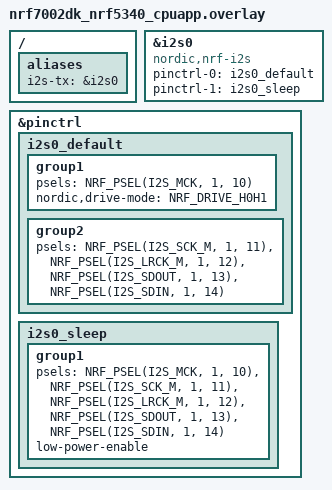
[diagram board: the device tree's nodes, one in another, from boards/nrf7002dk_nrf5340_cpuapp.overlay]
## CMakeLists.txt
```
#
# Copyright (c) 2022 Nordic Semiconductor ASA
#
# SPDX-License-Identifier: LicenseRef-Nordic-5-Clause
#

cmake_minimum_required(VERSION 3.20.0)

find_package(Zephyr REQUIRED HINTS $ENV{ZEPHYR_BASE})
project(nrf_wifi_audio_player)

FILE(GLOB app_sources src/*.c)


message("show app_sources::")
message("${app_sources}")

if (CONFIG_NRF700X_AP_MODE)
        list(FILTER app_sources EXCLUDE REGEX ".*wifi_station_mode\\.c$")
else()
        list(FILTER app_sources EXCLUDE REGEX ".*wifi_softap_mode\\.c$")
endif()

target_sources(app PRIVATE ${app_sources})
target_include_directories(app PRIVATE src)
target_include_directories(app PUBLIC ${ZEPHYR_BASE}/subsys/net/ip)
```

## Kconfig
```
#
# Copyright (c) 2022 Nordic Semiconductor
#
# SPDX-License-Identifier: LicenseRef-Nordic-5-Clause
#

source "Kconfig.zephyr"

menu "Nordic WiFi Auido Player"

if NRF700X_AP_MODE

config SAMPLE_SOCKET_TCP
	bool "Use TCP sockets"
	default n
	help
	  Enable this to use TCP instead of UDP for sockets.

config SOFTAP_DHCPV4_SERVER
	bool "DHCPv4 server"
	select NET_DHCPV4_SERVER
	default y
	help
	  Enable this to configure DHCPV4 server settings.

config SOFTAP_DHCPV4_POOL_START
	string "Start address of DHCPv4 pool"
	default "192.168.1.2"
	help
	  Set the start IP address of DHCPv4 pool.

config SOFTAP_REG_DOMAIN
	string "The ISO/IEC alpha2 country code"
	default "00"
	help
	  Set the ISO/IEC alpha2 country code for the country in
	  which the device is currently operating.
	  For world regulatory, use "00".

choice SOFTAP_FREQUENCY_BAND
	prompt "Wi-Fi frequency band for SoftAp"
	default SOFTAP_2_4GHz

config SOFTAP_2_4GHz
	bool "2.4 GHz band"
	help
	  Enable this option if the SoftAP should operate in the 2.4 GHz band.

config SOFTAP_5GHz
	bool "5 GHz band"
	help
	  Enable this option if the SoftAP should operate in the 5 GHz band.
	  Ensure that you have the appropriate regulatory settings configured.
endchoice

config SOFTAP_CHANNEL
	int "SoftAP channel"
	range 1 255
	default 1 if SOFTAP_2_4GHz
	default 36 if SOFTAP_5GHz
	help
	  Set the Wi-Fi channel on which the SoftAP will operate.

config SOFTAP_SSID
	string "SoftAP SSID"
	default "Myssid"
	help
	  Set the SSID (Service Set Identifier) for the SoftAP.
	  This is the name that will be broadcasted for client(s) to connect.

choice  SOFTAP_KEY_MGMT_SELECT
	prompt "Security option for SoftAP"
	default SOFTAP_KEY_MGMT_WPA2

config SOFTAP_KEY_MGMT_NONE
	bool "Open security"
	help
	  Enable for open security

config SOFTAP_KEY_MGMT_WPA2
	bool "WPA2 security"
	help
	  Enable for WPA2 security

config SOFTAP_KEY_MGMT_WPA2_256
	bool "WPA2 SHA 256 security"
	help
	  Enable for WPA2-PSK-256 security.

config SOFTAP_KEY_MGMT_WPA3
	bool "WPA3 security"
	help
	  Enable for WPA3 security.
endchoice

config SOFTAP_PASSWORD
	string "Passphrase (WPA2) or password (WPA3)"
	default "Mypassword"
	help
	  Set the password for SoftAP.

config SOFTAP_MAX_STATIONS
	int "Maximum number of stations"
	# Experimental support for one, but in future support for up to 8 (nRF70 limitation)
	range 1 1
	default 1
	help
	  Set the maximum number of stations allowed to connect to the SoftAP.

config SOFTAP_START_WIFI_THREAD_STACK_SIZE
	int "Stack size for Wi-Fi start thread"
	default 4096
	help
	  Set the stack size for the Wi-Fi start thread.   

endif #if NRF700X_AP_MODE

endmenu
```

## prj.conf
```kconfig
#
# Copyright (c) 2022 Nordic Semiconductor ASA
#
# SPDX-License-Identifier: LicenseRef-Nordic-5-Clause
#

# Wi-Fi
CONFIG_WIFI=y
CONFIG_WIFI_NRF700X=y

# WPA supplicant
CONFIG_WPA_SUPP=y

# Station Mode
# Configure the Wi-Fi credentials
CONFIG_WIFI_CREDENTIALS=y
CONFIG_WIFI_CREDENTIALS_STATIC=n
CONFIG_WIFI_CREDENTIALS_BACKEND_SETTINGS=y
CONFIG_FLASH=y
CONFIG_FLASH_PAGE_LAYOUT=y
CONFIG_FLASH_MAP=y
CONFIG_NVS=y
CONFIG_SETTINGS=y
CONFIG_SETTINGS_NVS=y
# Enable support for shell commands
CONFIG_SHELL=y
CONFIG_SHELL_STACK_SIZE=8192
CONFIG_WIFI_CREDENTIALS_SHELL=y

# Networking Management API
# Enable the Network Management relevant configurations
CONFIG_NET_MGMT=y
CONFIG_NET_MGMT_EVENT=y
CONFIG_NET_MGMT_EVENT_INFO=y
CONFIG_NET_MGMT_EVENT_STACK_SIZE=4096
CONFIG_NET_CONNECTION_MANAGER=y
#CONFIG_L2_WIFI_CONNECTIVITY=y

# Logging
CONFIG_LOG=y
CONFIG_LOG_DEFAULT_LEVEL=3

# DK library
CONFIG_DK_LIBRARY=y

# Networking
CONFIG_NETWORKING=y
CONFIG_NET_NATIVE=y
CONFIG_NET_SOCKETS=y
CONFIG_NET_LOG=y
CONFIG_NET_IPV4=y
CONFIG_NET_TCP=y
CONFIG_NET_UDP=y
CONFIG_NET_DHCPV4=y

CONFIG_NET_PKT_RX_COUNT=8
CONFIG_NET_PKT_TX_COUNT=8

# Below section is the primary contributor to SRAM and is currently
# tuned for performance, but this will be revisited in the future.
CONFIG_NET_BUF_RX_COUNT=16
CONFIG_NET_BUF_TX_COUNT=16
CONFIG_NET_BUF_DATA_SIZE=1500
CONFIG_HEAP_MEM_POOL_SIZE=153600
CONFIG_NET_TC_TX_COUNT=1

CONFIG_NET_IF_UNICAST_IPV4_ADDR_COUNT=1
CONFIG_NET_MAX_CONTEXTS=5
CONFIG_NET_CONTEXT_SYNC_RECV=y

CONFIG_INIT_STACKS=y

CONFIG_NET_L2_ETHERNET=y

CONFIG_NET_CONFIG_SETTINGS=y
CONFIG_NET_CONFIG_INIT_TIMEOUT=0

CONFIG_NET_SOCKETS_POLL_MAX=10

CONFIG_NET_CONFIG_MY_IPV4_ADDR="192.168.1.1"
CONFIG_NET_CONFIG_MY_IPV4_NETMASK="255.255.255.0"
CONFIG_NET_CONFIG_MY_IPV4_GW="192.168.1.1"

# printing of scan results puts pressure on queues in new locking
# design in net_mgmt. So, use a higher timeout for a crowded
# environment.
CONFIG_NET_MGMT_EVENT_QUEUE_TIMEOUT=5000

# Memories
CONFIG_MAIN_STACK_SIZE=8192
CONFIG_SYSTEM_WORKQUEUE_STACK_SIZE=4096
CONFIG_NET_TX_STACK_SIZE=8192
CONFIG_NET_RX_STACK_SIZE=8192

# Kernel options
CONFIG_ENTROPY_GENERATOR=y

CONFIG_DEBUG=y

# Enable I2S
CONFIG_I2S=y
CONFIG_I2S_LOG_LEVEL_ERR=y
```

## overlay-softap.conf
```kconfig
# Disable WiFi Station Mode first



# Enable Soft AP Mode
CONFIG_NRF700X_AP_MODE=y
CONFIG_WPA_SUPP_AP=y
CONFIG_WPA_SUPP_LOG_LEVEL_INF=y
CONFIG_WIFI_READY_LIB=y

CONFIG_SOFTAP_SAMPLE_5GHz=y
CONFIG_SOFTAP_SAMPLE_CHANNEL=36
CONFIG_SOFTAP_SAMPLE_REG_DOMAIN="NO"
CONFIG_SOFTAP_SAMPLE_SSID="WiFi_Audio_AP"
CONFIG_SOFTAP_SAMPLE_PASSWORD="Auido@WiFi"
CONFIG_FILE_SYSTEM=y
```

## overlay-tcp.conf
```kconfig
CONFIG_SAMPLE_SOCKET_TCP=y
```

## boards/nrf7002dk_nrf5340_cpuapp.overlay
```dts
/*
 * Copyright 2023 NXP
 *
 * SPDX-License-Identifier: Apache-2.0
 */

&i2s0 {
	compatible = "nordic,nrf-i2s";
	status = "okay";
	pinctrl-0 = <&i2s0_default>;
	pinctrl-1 = <&i2s0_sleep>;
	pinctrl-names = "default", "sleep";
};

&pinctrl {
	i2s0_default: i2s0_default {
		group1 {
			psels = <NRF_PSEL(I2S_MCK, 1, 10)>;
			nordic,drive-mode = <NRF_DRIVE_H0H1>;
		};
		group2 {
			psels = <NRF_PSEL(I2S_SCK_M, 1, 11)>,
				<NRF_PSEL(I2S_LRCK_M, 1, 12)>,
				<NRF_PSEL(I2S_SDOUT, 1, 13)>,
				<NRF_PSEL(I2S_SDIN, 1, 14)>;
		};
	};

	i2s0_sleep: i2s0_sleep {
		group1 {
			psels = <NRF_PSEL(I2S_MCK, 1, 10)>,
				<NRF_PSEL(I2S_SCK_M, 1, 11)>,
				<NRF_PSEL(I2S_LRCK_M, 1, 12)>,
				<NRF_PSEL(I2S_SDOUT, 1, 13)>,
				<NRF_PSEL(I2S_SDIN, 1, 14)>;
			low-power-enable;
		};
	};
};

/ {
	aliases {
		i2s-tx = &i2s0;
	};
};
```

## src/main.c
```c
/*
 * Copyright (c) 2022 Nordic Semiconductor ASA
 *
 * SPDX-License-Identifier: LicenseRef-Nordic-5-Clause
 */

/** @file
 * @brief WiFi station sample
 */

#include <zephyr/logging/log.h>
LOG_MODULE_REGISTER(wifi_to_i2s, CONFIG_LOG_DEFAULT_LEVEL);

#include <stdio.h>
#include <zephyr/kernel.h>
#include <zephyr/drivers/i2s.h>
#include <zephyr/sys/iterable_sections.h>
#include "socket_util.h"

const struct device *dev_i2s = DEVICE_DT_GET(DT_ALIAS(i2s_tx));

#define NUM_BLOCKS 10
#define BLOCK_SIZE BUFFER_MAX_SIZE

#define I2S_TIMEOUT_MS 100

#define I2S_THREAD_STACKSIZE 8192
#define I2S_THREAD_PRIORITY 8

#ifdef CONFIG_NOCACHE_MEMORY
	#define MEM_SLAB_CACHE_ATTR __nocache
#else
	#define MEM_SLAB_CACHE_ATTR
#endif /* CONFIG_NOCACHE_MEMORY */

static char MEM_SLAB_CACHE_ATTR __aligned(WB_UP(32))
	_k_mem_slab_buf_tx_0_mem_slab[(NUM_BLOCKS) * WB_UP(BLOCK_SIZE)];

static STRUCT_SECTION_ITERABLE(k_mem_slab, tx_0_mem_slab) =
	Z_MEM_SLAB_INITIALIZER(tx_0_mem_slab, _k_mem_slab_buf_tx_0_mem_slab,
				WB_UP(BLOCK_SIZE), NUM_BLOCKS);

static uint32_t i2s_running = false;

int i2s_recover(void)
{
    LOG_INF("I2S driver is likely in error state, trying to recover");
    int ret = i2s_trigger(dev_i2s, I2S_DIR_TX, I2S_TRIGGER_PREPARE);
    if (ret < 0) {
        LOG_ERR("Failed to recover I2S. Please reset board");
    }
    return ret;
}


int i2s_drain_tx(void)
{
    /* Drain TX queue */
	LOG_INF("Triggered DRAIN");
    int ret = i2s_trigger(dev_i2s, I2S_DIR_TX, I2S_TRIGGER_DRAIN);
    i2s_running = false;
	if (ret < 0) {
		LOG_ERR("I2S DRAIN not triggered correctly: %d", ret);
        //Try to fix by reconfiguring driver
        ret = i2s_recover();
        if(ret <0)
        {
            LOG_ERR("Could not recover I2S, please reset board");
            return ret;
        }
        LOG_INF("Recover successful!");
		return ret;
	}
    
}

int i2s_send_data(uint8_t *data, uint16_t len)
{
    int ret;
    int curr_block_idx = 0;
    void *tx_block[NUM_BLOCKS];

    if(!i2s_running)
    {
        ret = k_mem_slab_alloc(&tx_0_mem_slab, &tx_block[curr_block_idx], K_FOREVER);
        if(ret < 0)
        {
            LOG_ERR("Could not allocate memory slab: %d", ret);
            return ret;
        }
        memset(tx_block[curr_block_idx],0x00, BLOCK_SIZE);
        memcpy(tx_block[curr_block_idx], data, MIN(len, BLOCK_SIZE));
        /* Send first block */
        ret = i2s_write(dev_i2s, tx_block[curr_block_idx], BLOCK_SIZE);
        if (ret < 0) {
            LOG_ERR("Could not write I2S TX buffer %d", ret);
            return ret;
        }
        /* Trigger the I2S transmission */
        ret = i2s_trigger(dev_i2s, I2S_DIR_TX, I2S_TRIGGER_START);
        if (ret < 0) {
            LOG_ERR("Could not trigger I2S tx");
            return ret;
	    }
        curr_block_idx++;
        i2s_running = true;
    }
    
    while(len > BLOCK_SIZE * curr_block_idx)
    {
        ret = k_mem_slab_alloc(&tx_0_mem_slab, &tx_block[curr_block_idx], K_FOREVER);
        if(ret < 0)
        {
            LOG_ERR("Could not allocate memory slab: %d", ret);
            return ret;
        }
        memset(tx_block[curr_block_idx], 0x00, BLOCK_SIZE);
        memcpy(tx_block[curr_block_idx], (data + (BLOCK_SIZE * curr_block_idx)), MIN(len-curr_block_idx*BLOCK_SIZE, BLOCK_SIZE));
        /* Send remaining blocks */
        ret = i2s_write(dev_i2s, tx_block[curr_block_idx], MIN(len-curr_block_idx*BLOCK_SIZE, BLOCK_SIZE));
        if(ret == -EIO)
        {
            //If I2S write fails due to an internal error (buffer provided too later or drain triggered too early), try to recover to continue
            ret = i2s_recover();
            if(ret < 0)
            {
                LOG_ERR("Could not recover I2S, please reset board");
                return ret;
            }
            ret = i2s_write(dev_i2s, tx_block[curr_block_idx], MIN(len-curr_block_idx*BLOCK_SIZE, BLOCK_SIZE));
            if (ret < 0) {
                LOG_ERR("Could not recover I2S, please reset board");
                return ret;
            }
            /* Trigger the I2S transmission */
            ret = i2s_trigger(dev_i2s, I2S_DIR_TX, I2S_TRIGGER_START);
            if (ret < 0) {
                LOG_ERR("Could not recover I2S, please reset board");
                return ret;
            }
            
        }
        else if (ret < 0) {
            LOG_ERR("Could not write I2S TX buffer %d", ret);
            return ret;
        }
        
        curr_block_idx++;
    }
    return 0;
}



// void socket_rx_callback(uint8_t *data, uint16_t len)
// {
   
//     // Process data here before outputting on I2S.
//     i2s_send_data(data, len);

// }

int i2s_config(void)
{
	struct i2s_config i2s_cfg;
	int ret;	

	if (!device_is_ready(dev_i2s)) {
		printf("I2S device not ready\n");
		return -ENODEV;
	}
	/* Configure I2S stream */
	i2s_cfg.word_size = 16U;
	i2s_cfg.channels = 2U;
	i2s_cfg.format = I2S_FMT_DATA_FORMAT_I2S;
	i2s_cfg.frame_clk_freq = 44100;
	i2s_cfg.block_size = BLOCK_SIZE;
	i2s_cfg.timeout = SYS_FOREVER_MS;
	/* Configure the Transmit port as Master */
	i2s_cfg.options = I2S_OPT_FRAME_CLK_MASTER
			| I2S_OPT_BIT_CLK_MASTER;
	i2s_cfg.mem_slab = &tx_0_mem_slab;
	ret = i2s_configure(dev_i2s, I2S_DIR_TX, &i2s_cfg);
	if (ret < 0) {
		printf("Failed to configure I2S stream\n");
		return ret;
	}

    return 0;
}

int main(void)
{
        LOG_INF("WiFi to I2S streamer start");

        i2s_config();
        
}

void i2s_data_handler(void)
{
    static socket_receive_t socket_receive;
    while(1)
    {
        while (k_msgq_get(&socket_recv_queue, &socket_receive, K_MSEC(I2S_TIMEOUT_MS)) == 0) {
            i2s_send_data(socket_receive.buf, socket_receive.len);
        }
        
        if(i2s_running)
        {
            // If I2S is running and no incomming packet during timeout, trigger drain and stop I2S
            i2s_drain_tx();
        }
    }
}

K_THREAD_DEFINE(i2s_data_handler_id, I2S_THREAD_STACKSIZE,
                i2s_data_handler, NULL, NULL, NULL,
                I2S_THREAD_PRIORITY, 0, 0);
```

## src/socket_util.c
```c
/*
 * Copyright (c) 2024 Nordic Semiconductor ASA
 *
 * SPDX-License-Identifier: LicenseRef-Nordic-5-Clause
 */
#include <zephyr/logging/log.h>
LOG_MODULE_REGISTER(socket_util, CONFIG_LOG_DEFAULT_LEVEL);

#include <errno.h>
#include <stddef.h>
#include <string.h>
#include <stdio.h>
#include <zephyr/kernel.h>
#include <zephyr/types.h>
#include <zephyr/net/socket.h>
/* Macro called upon a fatal error, reboots the device. */
#include <zephyr/sys/reboot.h>
#include <dk_buttons_and_leds.h>
#include <zephyr/logging/log_ctrl.h>
#include "socket_util.h"

#define FATAL_ERROR()                              \
	LOG_ERR("Fatal error! Rebooting the device."); \
	LOG_PANIC();                                   \
	IF_ENABLED(CONFIG_REBOOT, (sys_reboot(0)))

/* size of stack area used by each thread */
#define STACKSIZE 8192
/* scheduling priority used by each thread */
#define PRIORITY 3


//#define pc_port  60000
#define socket_port 60010 // use for either udp or tcp server


/**********External Resources START**************/
extern int wifi_station_mode_ready(void);
extern int wifi_softap_mode_ready(void);
/**********External Resources END**************/

int udp_socket;
int tcp_server_listen_fd;
int tcp_server_socket;
struct sockaddr_in cam_addr;
bool socket_connected=false;

char pc_addr_str[32];
struct sockaddr_in pc_addr;
socklen_t pc_addr_len=sizeof(pc_addr);

/* Define the semaphore wifi_net_ready */
struct k_sem wifi_net_ready;
enum wifi_modes wifi_mode=WIFI_STATION_MODE;



static socket_receive_t socket_receive;

K_MSGQ_DEFINE(socket_recv_queue, sizeof(socket_receive), 1, 4);

static net_util_socket_rx_callback_t socket_rx_cb = 0; 

void net_util_set_callback(net_util_socket_rx_callback_t socket_rx_callback)
{
	socket_rx_cb = socket_rx_callback;

	// If any messages are waiting in the queue, forward them immediately
	socket_receive_t socket_receive;
	while (k_msgq_get(&socket_recv_queue, &socket_receive, K_NO_WAIT) == 0) {
		socket_rx_cb(socket_receive.buf, socket_receive.len);
	}
}

uint8_t process_socket_rx_buffer(char *socket_rx_buf, char *command_buf)
{
	uint8_t command_length = 0;

	// // Check if socket_rx_buf contains start code (0x55)
	// if (socket_rx_buf[0] == 0x55)
	// {
	// 	// Find the end code (0xAA) and extract the command
	// 	for (uint8_t i = 1; i < CAM_COMMAND_MAX_SIZE; i++)
	// 	{
	// 		if (socket_rx_buf[i] == 0xAA)
	// 		{
	// 			// Copy the command to command_buf
	// 			for (uint8_t j = 1; j < i; j++)
	// 			{
	// 				command_buf[j - 1] = socket_rx_buf[j];
	// 			}
	// 			command_length = i - 1; // Length of the command
	// 			break;
	// 		}
	// 	}
	// }
	return command_length;
}

static void trigger_socket_rx_callback_if_set()
{
	if (socket_rx_cb != 0) {
		socket_rx_cb(socket_receive.buf, socket_receive.len);
	} else {
		k_msgq_put(&socket_recv_queue, &socket_receive, K_NO_WAIT);
	}
}


void data_send(const void *buf, size_t len){
		#if defined(CONFIG_SAMPLE_SOCKET_TCP)
			if (send(tcp_server_socket, buf, len, 0) == -1) {
				perror("Sending failed");
				close(tcp_server_socket);
				FATAL_ERROR();
				return;
			}
		#else
			sendto(udp_socket, buf, len, 0, (struct sockaddr *)&pc_addr,  sizeof(pc_addr));
		#endif
}

/* Thread to setup WiFi, Network, Sockets step by step */
static void wifi_net_sockets(void)
{
	int ret;

	k_sem_init(&wifi_net_ready, 0, 1);

	if (dk_leds_init() != 0)
	{
		LOG_ERR("Failed to initialize the LED library");
	}

        #if defined(CONFIG_NRF700X_AP_MODE)
                ret = wifi_softap_mode_ready();
        #else
                ret = wifi_station_mode_ready();
        #endif
        
	if (ret < 0)
	{
		LOG_ERR("wifi network connection is not ready, error: %d", -errno);
		FATAL_ERROR();
		return;
	}

	cam_addr.sin_family = AF_INET;
	cam_addr.sin_addr.s_addr = htonl(INADDR_ANY);
	cam_addr.sin_port = htons(socket_port);

	#if defined(CONFIG_SAMPLE_SOCKET_TCP)
		tcp_server_listen_fd = socket(AF_INET, SOCK_STREAM, IPPROTO_TCP);
		
		if (tcp_server_listen_fd < 0)
		{
			LOG_ERR("Failed to create socket: %d", -errno);
			FATAL_ERROR();
			return;
		}
		
		ret = bind(tcp_server_listen_fd, (struct sockaddr *)&cam_addr, sizeof(cam_addr));
		if (ret < 0)
		{
			LOG_ERR("bind, error: %d", -errno);
			FATAL_ERROR();
			return;
		}

		ret = listen(tcp_server_listen_fd, 5);
		if (ret < 0)
		{
			LOG_ERR("listen, error: %d", -errno);
			FATAL_ERROR();
			return;
		}

		while(1){
			tcp_server_socket = accept(tcp_server_listen_fd, (struct sockaddr *)&pc_addr, &pc_addr_len);
			if (tcp_server_socket < 0)
			{
				LOG_ERR("accept, error: %d", -errno);
				FATAL_ERROR();
				return;
			}
			LOG_INF("Accepted connection from client\n");
			inet_ntop(pc_addr.sin_family, &pc_addr.sin_addr, pc_addr_str, sizeof(pc_addr_str));
			LOG_INF("Connect with PC through WiFi, PC IPAddr = %s, Port = %d\n", pc_addr_str, ntohs(pc_addr.sin_port));
			// Handle the client connection
			while((socket_receive.len = recv(tcp_server_socket, socket_receive.buf, BUFFER_MAX_SIZE,0))>0){
				k_msgq_put(&socket_recv_queue, &socket_receive, K_FOREVER);
                //trigger_socket_rx_callback_if_set();
			}
			if (socket_receive.len == -1) {
				LOG_ERR("Receiving failed");
			} else if (socket_receive.len == 0) {
				LOG_INF("Client disconnected.\n");
			}
			close(tcp_server_socket);
		}
		// Close the server socket (should be unreachable  as the server runs indefinitely)
		close(tcp_server_listen_fd);
	#else
		udp_socket = socket(AF_INET, SOCK_DGRAM, IPPROTO_UDP);
		if (udp_socket < 0)
		{
			LOG_ERR("Failed to create socket: %d", -errno);
			FATAL_ERROR();
			return;
		}
		ret = bind(udp_socket, (struct sockaddr *)&cam_addr, sizeof(cam_addr));
		if (ret < 0)
		{
			LOG_ERR("bind, error: %d", -errno);
			FATAL_ERROR();
			return;
		}
		while((socket_receive.len = recvfrom(udp_socket, socket_receive.buf, BUFFER_MAX_SIZE, 0, (struct sockaddr *)&pc_addr, &pc_addr_len))>0){
			if(socket_connected == false){
				inet_ntop(pc_addr.sin_family, &pc_addr.sin_addr, pc_addr_str, sizeof(pc_addr_str));
				LOG_INF("Connect with PC through WiFi, PC IPAddr = %s, Port = %d\n", pc_addr_str, ntohs(pc_addr.sin_port));
				socket_connected=true;
			}
            LOG_INF("Received %d bytes", socket_receive.len);
			trigger_socket_rx_callback_if_set();
		}
		if (socket_receive.len == -1) {
			LOG_ERR("Receiving failed");
		} else if (socket_receive.len == 0) {
			LOG_INF("Client disconnected.\n");
		}

		close(udp_socket);
		socket_connected=false;

	#endif
}

K_THREAD_DEFINE(wifi_net_sockets_id, STACKSIZE, wifi_net_sockets, NULL, NULL, NULL,
				PRIORITY, 0, 0);
```

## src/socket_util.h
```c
#ifndef __SOCKET_UTIL_H
#define __SOCKET_UTIL_H

#include <zephyr/kernel.h>

#define CAM_COMMAND_MAX_SIZE 6

enum wifi_modes {
        WIFI_STATION_MODE = 0,
        WIFI_SOFTAP_MODE,
};

typedef void (*net_util_socket_rx_callback_t)(uint8_t *data, uint16_t len);

void net_util_set_callback(net_util_socket_rx_callback_t socket_rx_callback);
void data_send(const void *buf, size_t len);

uint8_t process_socket_rx_buffer(char *udp_rx_buf, char *command_buf);

/* Same as COMMAND_MAX_SIZE*/
#define BUFFER_MAX_SIZE 1508

typedef struct {
    uint8_t buf[BUFFER_MAX_SIZE];
    uint32_t len;
} socket_receive_t;

extern struct k_msgq socket_recv_queue;

#endif
```

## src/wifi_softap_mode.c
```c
/*
 * Copyright (c) 2024 Nordic Semiconductor ASA
 *
 * SPDX-License-Identifier: LicenseRef-Nordic-5-Clause
 */

#include <zephyr/logging/log.h>
LOG_MODULE_REGISTER(wifi_softap_mode, CONFIG_LOG_DEFAULT_LEVEL);

#include <zephyr/net/wifi_mgmt.h>
#include <zephyr/net/wifi_utils.h>
#include "net_private.h"
#include <zephyr/net/dhcpv4_server.h>

#include <net/wifi_ready.h>

#define WIFI_SAP_MGMT_EVENTS (NET_EVENT_WIFI_AP_ENABLE_RESULT)

static K_SEM_DEFINE(wifi_ready_state_changed_sem, 0, 1);
static bool wifi_ready_status;

#include <dk_buttons_and_leds.h>

/**********External Resources START**************/
extern struct k_sem wifi_net_ready;
/**********External Resources END**************/
int wifi_softap_mode_ready(void);

static struct net_mgmt_event_callback wifi_sap_mgmt_cb;

static K_MUTEX_DEFINE(wifi_ap_sta_list_lock);
struct wifi_ap_sta_node {
	bool valid;
	struct wifi_ap_sta_info sta_info;
};
static struct wifi_ap_sta_node sta_list[CONFIG_SOFTAP_SAMPLE_MAX_STATIONS];
bool dhcp_server_configured;

static void wifi_ap_stations_unlocked(void)
{
	size_t id = 1;

	LOG_INF("AP stations:");
	LOG_INF("============");

	for (int i = 0; i < CONFIG_SOFTAP_SAMPLE_MAX_STATIONS; i++) {
		struct wifi_ap_sta_info *sta;
		uint8_t mac_string_buf[sizeof("xx:xx:xx:xx:xx:xx")];

		if (!sta_list[i].valid) {
			continue;
		}

		sta = &sta_list[i].sta_info;

		LOG_INF("Station %zu:", id++);
		LOG_INF("==========");
		LOG_INF("MAC: %s",
			net_sprint_ll_addr_buf(sta->mac,
					       WIFI_MAC_ADDR_LEN,
					       mac_string_buf,
					       sizeof(mac_string_buf)));
		LOG_INF("Link mode: %s", wifi_link_mode_txt(sta->link_mode));
		LOG_INF("TWT: %s", sta->twt_capable ? "Supported" : "Not supported");
	}

	if (id == 1) {
		LOG_INF("No stations connected");
	}
}

static void handle_wifi_ap_enable_result(struct net_mgmt_event_callback *cb)
{
	const struct wifi_status *status =
		(const struct wifi_status *)cb->info;

	if (status->status) {
		LOG_ERR("AP enable request failed (%d)", status->status);
	} else {
		LOG_INF("AP enable requested");
	}
}

static void handle_wifi_ap_sta_connected(struct net_mgmt_event_callback *cb)
{
	const struct wifi_ap_sta_info *sta_info =
		(const struct wifi_ap_sta_info *)cb->info;
	uint8_t mac_string_buf[sizeof("xx:xx:xx:xx:xx:xx")];
	int i;

	LOG_INF("Station connected: %s",
		net_sprint_ll_addr_buf(sta_info->mac, WIFI_MAC_ADDR_LEN,
				       mac_string_buf, sizeof(mac_string_buf)));

	k_mutex_lock(&wifi_ap_sta_list_lock, K_FOREVER);
	for (i = 0; i < CONFIG_SOFTAP_SAMPLE_MAX_STATIONS; i++) {
		if (!sta_list[i].valid) {
			sta_list[i].sta_info = *sta_info;
			sta_list[i].valid = true;
			break;
		}
	}

	if (i == CONFIG_SOFTAP_SAMPLE_MAX_STATIONS) {
		LOG_ERR("No space to store station info: "
			"Increase CONFIG_SOFTAP_SAMPLE_MAX_STATIONS");
	}

	wifi_ap_stations_unlocked();
	k_mutex_unlock(&wifi_ap_sta_list_lock);
	dk_set_led_on(DK_LED1);
        LOG_INF("\r\n\r\nWiFi is ready on nRF5340 Audio DK + nRF7002EK. Try to connect the socket(udp by default)from address 192.168.1.1:60010.\r\n");
        k_sem_give(&wifi_net_ready);

}

static void handle_wifi_ap_sta_disconnected(struct net_mgmt_event_callback *cb)
{
	const struct wifi_ap_sta_info *sta_info =
		(const struct wifi_ap_sta_info *)cb->info;
	uint8_t mac_string_buf[sizeof("xx:xx:xx:xx:xx:xx")];
	int i;

	LOG_INF("Station disconnected: %s",
		net_sprint_ll_addr_buf(sta_info->mac, WIFI_MAC_ADDR_LEN,
				       mac_string_buf, sizeof(mac_string_buf)));

	k_mutex_lock(&wifi_ap_sta_list_lock, K_FOREVER);
	for (i = 0; i < CONFIG_SOFTAP_SAMPLE_MAX_STATIONS; i++) {
		if (!sta_list[i].valid) {
			continue;
		}

		if (!memcmp(sta_list[i].sta_info.mac, sta_info->mac,
			    WIFI_MAC_ADDR_LEN)) {
			sta_list[i].valid = false;
			break;
		}
	}

	if (i == CONFIG_SOFTAP_SAMPLE_MAX_STATIONS) {
		LOG_WRN("No matching MAC address found in the list");
	}

	wifi_ap_stations_unlocked();
	k_mutex_unlock(&wifi_ap_sta_list_lock);
	dk_set_led_off(DK_LED1);
	k_sem_reset(&wifi_net_ready);
	LOG_INF("\r\nWi-Fi is disconnected. Ready for new Wi-Fi connection.\r\n");
	LOG_INF("\r\n\r\nRunning on WiFi SoftAP mode.\r\nPlease connect PC WiFi network to SSID 'WiFi_Audio_AP' and password 'Auido@WiFi'.\r\n");

}

static void wifi_mgmt_event_handler(struct net_mgmt_event_callback *cb,
				    uint32_t mgmt_event, struct net_if *iface)
{
	switch (mgmt_event) {
	case NET_EVENT_WIFI_AP_ENABLE_RESULT:
		handle_wifi_ap_enable_result(cb);
		break;
	case NET_EVENT_WIFI_AP_STA_CONNECTED:
		handle_wifi_ap_sta_connected(cb);
		break;
	case NET_EVENT_WIFI_AP_STA_DISCONNECTED:
		handle_wifi_ap_sta_disconnected(cb);
		break;
	default:
		break;
	}
}

static int __wifi_args_to_params(struct wifi_connect_req_params *params)
{
#ifdef CONFIG_SOFTAP_SAMPLE_2_4GHz
	params->band = WIFI_FREQ_BAND_2_4_GHZ;
#elif CONFIG_SOFTAP_SAMPLE_5GHz
	params->band = WIFI_FREQ_BAND_5_GHZ;
#endif
	params->channel = CONFIG_SOFTAP_SAMPLE_CHANNEL;

	/* SSID */
	params->ssid = CONFIG_SOFTAP_SAMPLE_SSID;
	params->ssid_length = strlen(params->ssid);
	if (params->ssid_length > WIFI_SSID_MAX_LEN) {
		LOG_ERR("SSID length is too long, expected is %d characters long",
			WIFI_SSID_MAX_LEN);
		return -1;
	}

#if defined(CONFIG_SOFTAP_SAMPLE_KEY_MGMT_WPA2)
	params->security = 1;
#elif defined(CONFIG_SOFTAP_SAMPLE_KEY_MGMT_WPA2_256)
	params->security = 2;
#elif defined(CONFIG_SOFTAP_SAMPLE_KEY_MGMT_WPA3)
	params->security = 3;
#else
	params->security = 0;
#endif

#if !defined(CONFIG_SOFTAP_SAMPLE_KEY_MGMT_NONE)
	params->psk = CONFIG_SOFTAP_SAMPLE_PASSWORD;
	params->psk_length = strlen(params->psk);
#endif

	return 0;
}

static void cmd_wifi_status(void)
{
	struct net_if *iface;
	struct wifi_iface_status status = { 0 };

	iface = net_if_get_first_wifi();
	if (!iface) {
		LOG_ERR("Failed to get Wi-FI interface");
		return;
	}

	if (net_mgmt(NET_REQUEST_WIFI_IFACE_STATUS, iface, &status,
				sizeof(struct wifi_iface_status))) {
		LOG_ERR("Status request failed");
		return;
	}

	LOG_INF("Status: successful");
	LOG_INF("==================");
	LOG_INF("State: %s", wifi_state_txt(status.state));

	if (status.state >= WIFI_STATE_ASSOCIATED) {
		uint8_t mac_string_buf[sizeof("xx:xx:xx:xx:xx:xx")];

		LOG_INF("Interface Mode: %s", wifi_mode_txt(status.iface_mode));
		LOG_INF("Link Mode: %s", wifi_link_mode_txt(status.link_mode));
		LOG_INF("SSID: %.32s", status.ssid);
		LOG_INF("BSSID: %s",
			net_sprint_ll_addr_buf(status.bssid,
					       WIFI_MAC_ADDR_LEN, mac_string_buf,
					       sizeof(mac_string_buf)));
		LOG_INF("Band: %s", wifi_band_txt(status.band));
		LOG_INF("Channel: %d", status.channel);
		LOG_INF("Security: %s", wifi_security_txt(status.security));
		LOG_INF("MFP: %s", wifi_mfp_txt(status.mfp));
		LOG_INF("Beacon Interval: %d", status.beacon_interval);
		LOG_INF("DTIM: %d", status.dtim_period);
		LOG_INF("TWT: %s",
			status.twt_capable ? "Supported" : "Not supported");
	}
}

static int wifi_softap_enable(void)
{
	struct net_if *iface;
	static struct wifi_connect_req_params cnx_params;
	int ret = -1;

	iface = net_if_get_first_wifi();
	if (!iface) {
		LOG_ERR("Failed to get Wi-Fi iface");
		goto out;
	}

	if (__wifi_args_to_params(&cnx_params)) {
		goto out;
	}

	if (!wifi_utils_validate_chan(cnx_params.band, cnx_params.channel)) {
		LOG_ERR("Invalid channel %d in %d band",
			cnx_params.channel, cnx_params.band);
		goto out;
	}

	ret = net_mgmt(NET_REQUEST_WIFI_AP_ENABLE, iface, &cnx_params,
		       sizeof(struct wifi_connect_req_params));
	if (ret) {
		LOG_ERR("AP mode enable failed: %s", strerror(-ret));
	} else {
		LOG_INF("AP mode enabled");
	}

out:
	return ret;
}

static int wifi_set_reg_domain(void)
{
	struct net_if *iface;
	struct wifi_reg_domain regd = {0};
	int ret = -1;

	iface = net_if_get_first_wifi();
	if (!iface) {
		LOG_ERR("Failed to get Wi-Fi iface");
		return ret;
	}

	regd.oper = WIFI_MGMT_SET;
	strncpy(regd.country_code, CONFIG_SOFTAP_SAMPLE_REG_DOMAIN,
		(WIFI_COUNTRY_CODE_LEN + 1));

	ret = net_mgmt(NET_REQUEST_WIFI_REG_DOMAIN, iface,
		       &regd, sizeof(regd));
	if (ret) {
		LOG_ERR("Cannot %s Regulatory domain: %d", "SET", ret);
	} else {
		LOG_INF("Regulatory domain set to %s", CONFIG_SOFTAP_SAMPLE_REG_DOMAIN);
	}

	return ret;
}

static int configure_dhcp_server(void)
{
	struct net_if *iface;
	struct in_addr pool_start;
	int ret = -1;

	iface = net_if_get_first_wifi();
	if (!iface) {
		LOG_ERR("Failed to get Wi-Fi interface");
		goto out;
	}

	if (net_addr_pton(AF_INET, CONFIG_SOFTAP_SAMPLE_DHCPV4_POOL_START, &pool_start.s_addr)) {
		LOG_ERR("Invalid address: %s", CONFIG_SOFTAP_SAMPLE_DHCPV4_POOL_START);
		goto out;
	}

	ret = net_dhcpv4_server_start(iface, &pool_start);
	if (ret == -EALREADY) {
		dhcp_server_configured = true;
		LOG_ERR("DHCPv4 server already running on interface");
	} else if (ret < 0) {
		LOG_ERR("DHCPv4 server failed to start and returned %d error", ret);
	} else {
		dhcp_server_configured = true;
		LOG_INF("DHCPv4 server started and pool address starts from %s",
			CONFIG_SOFTAP_SAMPLE_DHCPV4_POOL_START);
	}
out:
	return ret;
}

#define CHECK_RET(func, ...) \
	do { \
		ret = func(__VA_ARGS__); \
		if (ret) { \
			LOG_ERR("Failed to configure %s", #func); \
			return -1; \
		} \
	} while (0)

static int start_app(void)
{
	int ret;

	CHECK_RET(wifi_set_reg_domain);

	CHECK_RET(configure_dhcp_server);

	CHECK_RET(wifi_softap_enable);

	cmd_wifi_status();

        LOG_INF("\r\n\r\nRunning on WiFi SoftAP mode.\r\nPlease connect PC WiFi network to SSID 'WiFi_Audio_AP' and password 'Auido@WiFi'.\r\n");
        k_sem_take(&wifi_net_ready, K_FOREVER);
	return 0;
}

static int stop_dhcp_server(void)
{
	int ret;

	struct net_if *iface = net_if_get_first_wifi();

	if (!iface) {
		LOG_ERR("Failed to get Wi-Fi interface");
		return -1;
	}

	ret = net_dhcpv4_server_stop(iface);
	if (ret) {
		LOG_ERR("Failed to stop DHCPv4 server, error: %d", ret);
	}

	dhcp_server_configured = false;
	LOG_INF("DHCPv4 server stopped");

	return ret;
}

static void start_wifi_thread(void);
#define THREAD_PRIORITY K_PRIO_COOP(CONFIG_NUM_COOP_PRIORITIES - 1)
K_THREAD_DEFINE(start_wifi_ap_thread_id, CONFIG_SOFTAP_SAMPLE_START_WIFI_THREAD_STACK_SIZE,
		start_wifi_thread, NULL, NULL, NULL,
		THREAD_PRIORITY, 0, -1);

static void start_wifi_thread(void)
{
	bool waiting_for_wifi = true;

	while (1) {
		int ret;

		if (waiting_for_wifi) {
			LOG_INF("Waiting for Wi-Fi to be ready");
		}

		ret = k_sem_take(&wifi_ready_state_changed_sem, K_FOREVER);
		if (ret) {
			LOG_ERR("Failed to take semaphore: %d", ret);
			return;
		}

		if (!wifi_ready_status) {
			LOG_INF("Wi-Fi is not ready");
			if (dhcp_server_configured) {
				stop_dhcp_server();
			}
			waiting_for_wifi = true;
			continue;
		}
		start_app();
		waiting_for_wifi = false;
	}
}

static void wifi_ready_cb(bool wifi_ready)
{
	LOG_DBG("Is Wi-Fi ready?: %s", wifi_ready ? "yes" : "no");
	wifi_ready_status = wifi_ready;
	k_sem_give(&wifi_ready_state_changed_sem);
}


static int register_wifi_ready(void)
{
	int ret = 0;
	wifi_ready_callback_t cb;
	struct net_if *iface = net_if_get_first_wifi();

	if (!iface) {
		LOG_ERR("Failed to get Wi-Fi interface");
		return -1;
	}

	cb.wifi_ready_cb = wifi_ready_cb;

	LOG_DBG("Registering Wi-Fi ready callbacks");
	ret = register_wifi_ready_callback(cb, iface);
	if (ret) {
		LOG_ERR("Failed to register Wi-Fi ready callbacks %s", strerror(ret));
		return ret;
	}

	return ret;
}


static void net_mgmt_callback_init(void)
{
	net_mgmt_init_event_callback(&wifi_sap_mgmt_cb,
				     wifi_mgmt_event_handler,
				     WIFI_SAP_MGMT_EVENTS);

	net_mgmt_add_event_callback(&wifi_sap_mgmt_cb);
}


int wifi_softap_mode_ready(void)
{
	int ret = 0;

        dhcp_server_configured = false;

        net_mgmt_callback_init();
        ret = register_wifi_ready();
	if (ret) {
		return ret;
	}
	k_thread_start(start_wifi_ap_thread_id);

	return ret;
}
```
